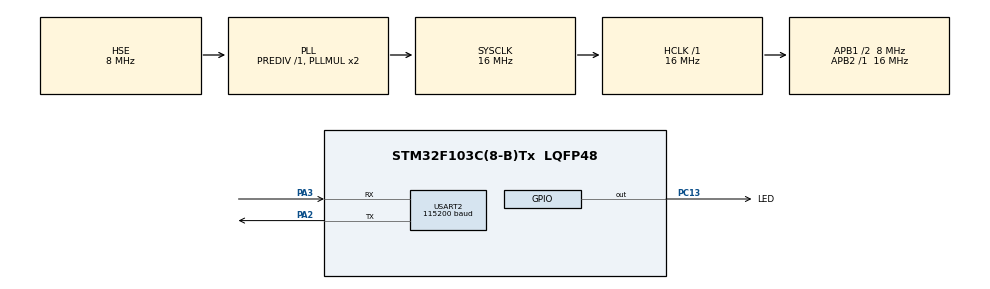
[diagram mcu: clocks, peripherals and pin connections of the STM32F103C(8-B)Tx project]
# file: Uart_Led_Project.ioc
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FREERTOS.INCLUDE_vTaskDelayUntil=1
FREERTOS.Tasks01=defaultTask,0,128,StartDefaultTask,Default,NULL,Dynamic,NULL,NULL
Mcu.Family=STM32F1
Mcu.Name=STM32F103C(8-B)Tx
Mcu.Package=LQFP48
NVIC.PriorityGroup=NVIC_PRIORITYGROUP_4
NVIC.TIM1_UP_IRQn=true\:0\:0\:false\:false\:true\:false\:false\:true
NVIC.TimeBase=TIM1_UP_IRQn
NVIC.TimeBaseIP=TIM1
NVIC.USART2_IRQn=true\:5\:0\:false\:false\:true\:true\:true\:true
PA13.Mode=Serial_Wire
PA13.Signal=SYS_JTMS-SWDIO
PA14.Mode=Serial_Wire
PA14.Signal=SYS_JTCK-SWCLK
PA2.Mode=Asynchronous
PA2.Signal=USART2_TX
PA3.Mode=Asynchronous
PA3.Signal=USART2_RX
PC13-TAMPER-RTC.GPIO_Label=LED
PC13-TAMPER-RTC.GPIO_ModeDefaultOutputPP=GPIO_MODE_OUTPUT_PP
PC13-TAMPER-RTC.GPIO_PuPd=GPIO_NOPULL
PC13-TAMPER-RTC.GPIO_Speed=GPIO_SPEED_FREQ_LOW
PC13-TAMPER-RTC.PinState=GPIO_PIN_RESET
PC13-TAMPER-RTC.Signal=GPIO_Output
PD0-OSC_IN.Mode=HSE-External-Oscillator
PD0-OSC_IN.Signal=RCC_OSC_IN
PD1-OSC_OUT.Mode=HSE-External-Oscillator
PD1-OSC_OUT.Signal=RCC_OSC_OUT
ProjectManager.HeapSize=0x200
ProjectManager.StackSize=0x400
ProjectManager.TargetToolchain=MDK-ARM V5.27
RCC.AHBFreq_Value=16000000
RCC.APB1CLKDivider=RCC_HCLK_DIV2
RCC.APB1Freq_Value=8000000
RCC.APB1TimFreq_Value=16000000
RCC.APB2Freq_Value=16000000
RCC.APB2TimFreq_Value=16000000
RCC.HCLKFreq_Value=16000000
RCC.PLLSourceVirtual=RCC_PLLSOURCE_HSE
RCC.SYSCLKFreq_VALUE=16000000
RCC.SYSCLKSource=RCC_SYSCLKSOURCE_PLLCLK
RCC.USBFreq_Value=16000000
USART2.BaudRate=115200
USART2.VirtualMode=VM_ASYNC
VP_FREERTOS_VS_CMSIS_V1.Mode=CMSIS_V1
VP_SYS_VS_tim1.Mode=TIM1
board=custom

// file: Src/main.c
/* USER CODE BEGIN Header */
/**
  ******************************************************************************
  * @file           : main.c
  * @brief          : Main program body
  ******************************************************************************
  * @attention
  *
  * <h2><center>&copy; Copyright (c) 2022 STMicroelectronics.
  * All rights reserved.</center></h2>
  *
  * This software component is licensed by ST under BSD 3-Clause license,
  * the "License"; You may not use this file except in compliance with the
  * License. You may obtain a copy of the License at:
  *                        opensource.org/licenses/BSD-3-Clause
  *
  ******************************************************************************
  */
/* USER CODE END Header */

#include "main.h"
#include "cmsis_os.h"
#include "usart.h"
#include "gpio.h"

/* USER CODE BEGIN Includes */
	#include "stdio.h"
	#include "stdlib.h"
	#include "string.h"
/* USER CODE END Includes */

/* USER CODE BEGIN PD */
enum led {Passive,Activate,StopMode,StartMode};
enum Communication{Communication_OFF,Communication_ON};

/* USER CODE END PD */

/* USER CODE BEGIN PM */
uint8_t rxTempBuffer[10];
uint8_t rxIndex=0;
uint8_t *rxBuffer;
uint16_t ledOffTimeCount=0;
uint16_t ledOnTimeCount=0;
char compareString[]="=";
char *ptrTime1;
char *ptrTime2;
char stringVal[10];
uint8_t startStopFlag=0;
uint8_t ledActivePasive=0;
uint8_t LedMODE=3;
uint8_t DataComplate=0;
/* USER CODE END PM */

void SystemClock_Config(void);
void MX_FREERTOS_Init(void);

/* USER CODE BEGIN 0 */
void HAL_UART_RxCpltCallback(UART_HandleTypeDef *huart)
{
	if(huart == &huart2) // if data is send another uart section, does not care data!
	{

		rxBuffer[rxIndex]=rxTempBuffer[0];
		if(rxBuffer[rxIndex]=='\0') //if all data came until NULL, compare string.
		{
			if((rxBuffer[2]=='o')||(rxBuffer[2]=='O')) //Control of STOP
			{
				startStopFlag=Communication_OFF;
				LedMODE=StopMode;               // interval 1 second blink led
				DataComplate=0;									// Stop Uart echo flag
			}
			else if((rxBuffer[2]=='a')||(rxBuffer[2]=='A')) // Control of START
			{
				startStopFlag=Communication_ON;
				LedMODE=StartMode;
				DataComplate=1;   //Uart echo for interval of 1 sn
			}
			else
			{
				if((rxBuffer[4]=='f')||(rxBuffer[4]=='F'))  // if ledoff data comes, get timer val!
				{
					ptrTime1=strstr((char *)rxBuffer,compareString); //Compare until =
					strcpy(stringVal,ptrTime1+1);   // Get value after '='
					ledOffTimeCount=atoi(stringVal);  //Convert led time
				}
				else if((rxBuffer[4]=='n')||(rxBuffer[4]=='N')) // if ledon data comes, get timer val!
				{
					ptrTime2=strstr((char *)rxBuffer,compareString); //Compare until =
					strcpy(stringVal,ptrTime2+1);   // Get value after '='
					ledOnTimeCount=atoi(stringVal);  //Convert led time to integer value
				}
			}
			rxIndex=0; //start over!
		}
		rxIndex++;

		HAL_UART_Receive_IT(&huart2,rxTempBuffer,1);  // created intterupt
	}

}
void StartDefaultTask(void const * argument);

uint8_t indx=0;

osThreadId defaultTaskHandle;
osThreadId Task2handler;
void task2_init (void const * argument);
/* USER CODE END 0 */

int main(void)
{

  /* MCU Configuration--------------------------------------------------------*/

  /* Reset of all peripherals, Initializes the Flash interface and the Systick. */
  HAL_Init();

  /* Configure the system clock */
  SystemClock_Config();

  /* Initialize all configured peripherals */
  MX_GPIO_Init();
  MX_USART2_UART_Init();
  /* USER CODE BEGIN 2 */
	HAL_UART_Receive_IT(&huart2,rxTempBuffer,1);  // created intterupt
  /* USER CODE END 2 */

  /* Call init function for freertos objects (in freertos.c) */
  MX_FREERTOS_Init();
  /* Start scheduler */
  osThreadDef(defaultTask, StartDefaultTask, osPriorityNormal, 0, 128);
  defaultTaskHandle = osThreadCreate(osThread(defaultTask), NULL);

	osThreadDef(Task2,task2_init,osPriorityAboveNormal,0,128);  //UART TASK Created!

	Task2handler=osThreadCreate(osThread(Task2),NULL);

  osKernelStart();

  /* We should never get here as control is now taken by the scheduler */
  /* Infinite loop */
  while (1)
  {

    /* USER CODE BEGIN 3 */
		// StartDefaultTask used as Led task!!!!!!!!!!!!!!!
		// task2 used as deciding uart task!!!!!!!!!!!!!!!
  }
  /* USER CODE END 3 */
}

void SystemClock_Config(void)
{
  RCC_OscInitTypeDef RCC_OscInitStruct = {0};
  RCC_ClkInitTypeDef RCC_ClkInitStruct = {0};

  /** Initializes the CPU, AHB and APB busses clocks
  */
  RCC_OscInitStruct.OscillatorType = RCC_OSCILLATORTYPE_HSE;
  RCC_OscInitStruct.HSEState = RCC_HSE_ON;
  RCC_OscInitStruct.HSEPredivValue = RCC_HSE_PREDIV_DIV1;
  RCC_OscInitStruct.HSIState = RCC_HSI_ON;
  RCC_OscInitStruct.PLL.PLLState = RCC_PLL_ON;
  RCC_OscInitStruct.PLL.PLLSource = RCC_PLLSOURCE_HSE;
  RCC_OscInitStruct.PLL.PLLMUL = RCC_PLL_MUL2;
  if (HAL_RCC_OscConfig(&RCC_OscInitStruct) != HAL_OK)
  {
    Error_Handler();
  }
  /** Initializes the CPU, AHB and APB busses clocks
  */
  RCC_ClkInitStruct.ClockType = RCC_CLOCKTYPE_HCLK|RCC_CLOCKTYPE_SYSCLK
                              |RCC_CLOCKTYPE_PCLK1|RCC_CLOCKTYPE_PCLK2;
  RCC_ClkInitStruct.SYSCLKSource = RCC_SYSCLKSOURCE_PLLCLK;
  RCC_ClkInitStruct.AHBCLKDivider = RCC_SYSCLK_DIV1;
  RCC_ClkInitStruct.APB1CLKDivider = RCC_HCLK_DIV2;
  RCC_ClkInitStruct.APB2CLKDivider = RCC_HCLK_DIV1;

  if (HAL_RCC_ClockConfig(&RCC_ClkInitStruct, FLASH_LATENCY_1) != HAL_OK)
  {
    Error_Handler();
  }
}
/* USER CODE BEGIN 4 */
void StartDefaultTask(void const * argument)       //LED TASK!
{
	static uint16_t ledTimeCount=0;
	static uint16_t ledStopTimeCount=0;

  /* USER CODE BEGIN StartDefaultTask */
  /* Infinite loop */
  for(;;)
  {
		if(LedMODE==StopMode)
		{
			ledStopTimeCount++;
			if((ledStopTimeCount==1000)&&(ledActivePasive==Passive))  //LED is ON interval of 1 second
			{
				HAL_GPIO_WritePin(GPIOC,LED_Pin,GPIO_PIN_RESET); //LED is ON
				ledStopTimeCount=0;
				ledActivePasive=Activate;
			}
			else if((ledStopTimeCount==1000)&&(ledActivePasive==Activate)) //LED is OFF interval of 1 second
			{
				HAL_GPIO_WritePin(GPIOC,LED_Pin,GPIO_PIN_SET);  //LED is OFF
				ledStopTimeCount=0;
				ledActivePasive=Passive;
			}
			ledTimeCount=0; //start over for UART StartMode
		}
		else if(LedMODE==StartMode)
		{
			ledTimeCount++;
			if((ledOnTimeCount==ledTimeCount)&&(ledActivePasive==Passive))  //if LED is ON
			{
				HAL_GPIO_WritePin(GPIOC,LED_Pin,GPIO_PIN_RESET); //LED is ON
				ledTimeCount=0;
				ledActivePasive=Activate;
			}
			else if((ledOffTimeCount==ledTimeCount)&&(ledActivePasive==Activate)) //if LED is OFF
			{
				HAL_GPIO_WritePin(GPIOC,LED_Pin,GPIO_PIN_SET);  //LED is OFF
				ledTimeCount=0;
				ledActivePasive=Passive;
			}
		}

    osDelay(1);
  }
  /* USER CODE END StartDefaultTask */
}

void task2_init (void const * argument) //send start data echo interval of 1 second period
{

	while(1)
	{
		if(DataComplate==1) //if all data came until NULL, compare string.
		{
			HAL_UART_Transmit_IT(&huart2,(uint8_t *) "start \r\n",8);
		}
		osDelay(1000);
	}

}

/* USER CODE END 4 */

 /**
  * @brief  Period elapsed callback in non blocking mode
  * @note   This function is called  when TIM1 interrupt took place, inside
  * HAL_TIM_IRQHandler(). It makes a direct call to HAL_IncTick() to increment
  * a global variable "uwTick" used as application time base.
  * @param  htim : TIM handle
  * @retval None
  */
void HAL_TIM_PeriodElapsedCallback(TIM_HandleTypeDef *htim)
{
  if (htim->Instance == TIM1) {
    HAL_IncTick();
  }
}

void Error_Handler(void)
{
}

/************************ (C) COPYRIGHT STMicroelectronics *****END OF FILE****/

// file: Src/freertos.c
/* USER CODE BEGIN Header */
/**
  ******************************************************************************
  * File Name          : freertos.c
  * Description        : Code for freertos applications
  ******************************************************************************
  * @attention
  *
  * <h2><center>&copy; Copyright (c) 2022 STMicroelectronics.
  * All rights reserved.</center></h2>
  *
  * This software component is licensed by ST under Ultimate Liberty license
  * SLA0044, the "License"; You may not use this file except in compliance with
  * the License. You may obtain a copy of the License at:
  *                             www.st.com/SLA0044
  *
  ******************************************************************************
  */
/* USER CODE END Header */

#include "FreeRTOS.h"
#include "task.h"
#include "main.h"
#include "cmsis_os.h"

void StartDefaultTask(void const * argument);

void MX_FREERTOS_Init(void); /* (MISRA C 2004 rule 8.1) */

/* GetIdleTaskMemory prototype (linked to static allocation support) */
void vApplicationGetIdleTaskMemory( StaticTask_t **ppxIdleTaskTCBBuffer, StackType_t **ppxIdleTaskStackBuffer, uint32_t *pulIdleTaskStackSize );

/* USER CODE BEGIN GET_IDLE_TASK_MEMORY */
static StaticTask_t xIdleTaskTCBBuffer;
static StackType_t xIdleStack[configMINIMAL_STACK_SIZE];

void vApplicationGetIdleTaskMemory( StaticTask_t **ppxIdleTaskTCBBuffer, StackType_t **ppxIdleTaskStackBuffer, uint32_t *pulIdleTaskStackSize )
{
  *ppxIdleTaskTCBBuffer = &xIdleTaskTCBBuffer;
  *ppxIdleTaskStackBuffer = &xIdleStack[0];
  *pulIdleTaskStackSize = configMINIMAL_STACK_SIZE;
  /* place for user code */
}
/* USER CODE END GET_IDLE_TASK_MEMORY */

void MX_FREERTOS_Init(void) {

  /* Create the thread(s) */
  /* definition and creation of defaultTask */

}

/************************ (C) COPYRIGHT STMicroelectronics *****END OF FILE****/
